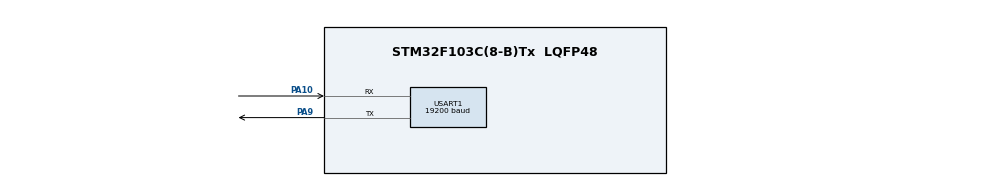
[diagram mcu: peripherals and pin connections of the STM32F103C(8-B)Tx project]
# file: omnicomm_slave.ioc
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Mcu.Family=STM32F1
Mcu.Name=STM32F103C(8-B)Tx
Mcu.Package=LQFP48
NVIC.PriorityGroup=NVIC_PRIORITYGROUP_4
NVIC.TIM2_IRQn=true\:15\:0\:false\:false\:true\:false\:true\:true
NVIC.TimeBase=TIM2_IRQn
NVIC.TimeBaseIP=TIM2
NVIC.USART1_IRQn=true\:0\:0\:false\:false\:true\:true\:true\:true
PA10.Mode=Asynchronous
PA10.Signal=USART1_RX
PA13.Mode=Serial_Wire
PA13.Signal=SYS_JTMS-SWDIO
PA14.Mode=Serial_Wire
PA14.Signal=SYS_JTCK-SWCLK
PA9.Mode=Asynchronous
PA9.Signal=USART1_TX
PD0-OSC_IN.Mode=HSE-External-Oscillator
PD0-OSC_IN.Signal=RCC_OSC_IN
PD1-OSC_OUT.Mode=HSE-External-Oscillator
PD1-OSC_OUT.Signal=RCC_OSC_OUT
ProjectManager.HeapSize=0x200
ProjectManager.StackSize=0x400
ProjectManager.TargetToolchain=STM32CubeIDE
RCC.AHBFreq_Value=72000000
RCC.APB1CLKDivider=RCC_HCLK_DIV2
RCC.APB1Freq_Value=36000000
RCC.APB1TimFreq_Value=72000000
RCC.APB2Freq_Value=72000000
RCC.APB2TimFreq_Value=72000000
RCC.HCLKFreq_Value=72000000
RCC.PLLMUL=RCC_PLL_MUL9
RCC.PLLSourceVirtual=RCC_PLLSOURCE_HSE
RCC.SYSCLKFreq_VALUE=72000000
RCC.SYSCLKSource=RCC_SYSCLKSOURCE_PLLCLK
RCC.USBFreq_Value=72000000
USART1.BaudRate=19200
USART1.VirtualMode=VM_ASYNC
VP_SYS_VS_tim2.Mode=TIM2
board=custom

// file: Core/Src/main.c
/* USER CODE BEGIN Header */
/**
  ******************************************************************************
  * @file           : main.c
  * @brief          : Main program body
  ******************************************************************************
  * @attention
  *
  * Copyright (c) 2025 STMicroelectronics.
  * All rights reserved.
  *
  * This software is licensed under terms that can be found in the LICENSE file
  * in the root directory of this software component.
  * If no LICENSE file comes with this software, it is provided AS-IS.
  *
  ******************************************************************************
  */
/* USER CODE END Header */
#include "main.h"
#include "usart.h"
#include "gpio.h"

/* USER CODE BEGIN Includes */
#include "ring_buf.h"
#include "transceiver.h"
#include "sensor.h"
#include <string.h>
#include "crc.h"
/* USER CODE END Includes */

void SystemClock_Config(void);

/* USER CODE BEGIN 0 */
RING_buffer_t rx_buff;
RING_buffer_t have_cmd;
/* USER CODE END 0 */

int main(void)
{

  /* MCU Configuration--------------------------------------------------------*/

  /* Reset of all peripherals, Initializes the Flash interface and the Systick. */
  HAL_Init();

  /* Configure the system clock */
  SystemClock_Config();

  /* Initialize all configured peripherals */
  MX_GPIO_Init();
  MX_USART1_UART_Init();
  /* USER CODE BEGIN 2 */
    LL_USART_EnableIT_RXNE(USART1);
    LL_USART_EnableIT_ERROR(USART1);

    SysTick_Config(SystemCoreClock/1000);   //Для генерации псевдослучайных чисел в функции sensor_get_data.

    uint8_t rxbuff_data[RING_BUFF_SZ];
    uint8_t havecmd_data[RING_BUFF_SZ];

    RING_init(&rx_buff, rxbuff_data, RING_BUFF_SZ);             //Инициализация кольцевых буферов
    RING_init(&have_cmd, havecmd_data, RING_BUFF_SZ);           //Инициализация кольцевых буферов

    Sensor_data_t sens_data;        //Создаём структуру для хранения значений полученных от датчика
    memset(&sens_data, 0x00, sizeof(Sensor_data_t));
  /* USER CODE END 2 */

  /* Infinite loop */
  /* USER CODE BEGIN WHILE */
  while (1)
  {
      if (RING_get_count(&rx_buff) >= REQ_SZ) {
          transceiver_get_msg(&rx_buff);
      }

      if (RING_get_count(&have_cmd) > 0) {
          uint8_t cmd = RING_pop(&have_cmd);
          if (cmd == CMD_GET_DATA) {
              sensor_get_data(&sens_data);
              transceiver_send_msg((uint8_t*)&sens_data, sizeof(Sensor_data_t));

          } else if (cmd == CMD_EXAMPLE) {
              /*
                ANY code
              */
          }
      }

      LL_mDelay(100);
    /* USER CODE END WHILE */
  }
}

void SystemClock_Config(void)
{
  LL_FLASH_SetLatency(LL_FLASH_LATENCY_2);
  while(LL_FLASH_GetLatency()!= LL_FLASH_LATENCY_2)
  {
  }
  LL_RCC_HSE_Enable();

   /* Wait till HSE is ready */
  while(LL_RCC_HSE_IsReady() != 1)
  {

  }
  LL_RCC_PLL_ConfigDomain_SYS(LL_RCC_PLLSOURCE_HSE_DIV_1, LL_RCC_PLL_MUL_9);
  LL_RCC_PLL_Enable();

   /* Wait till PLL is ready */
  while(LL_RCC_PLL_IsReady() != 1)
  {

  }
  LL_RCC_SetAHBPrescaler(LL_RCC_SYSCLK_DIV_1);
  LL_RCC_SetAPB1Prescaler(LL_RCC_APB1_DIV_2);
  LL_RCC_SetAPB2Prescaler(LL_RCC_APB2_DIV_1);
  LL_RCC_SetSysClkSource(LL_RCC_SYS_CLKSOURCE_PLL);

   /* Wait till System clock is ready */
  while(LL_RCC_GetSysClkSource() != LL_RCC_SYS_CLKSOURCE_STATUS_PLL)
  {

  }
  LL_SetSystemCoreClock(72000000);

   /* Update the time base */
  if (HAL_InitTick (TICK_INT_PRIORITY) != HAL_OK)
  {
    Error_Handler();
  }
}

void HAL_TIM_PeriodElapsedCallback(TIM_HandleTypeDef *htim)
{
  if (htim->Instance == TIM2) {
    HAL_IncTick();
  }
}

void Error_Handler(void)
{
  __disable_irq();
  while (1)
  {
  }
}
